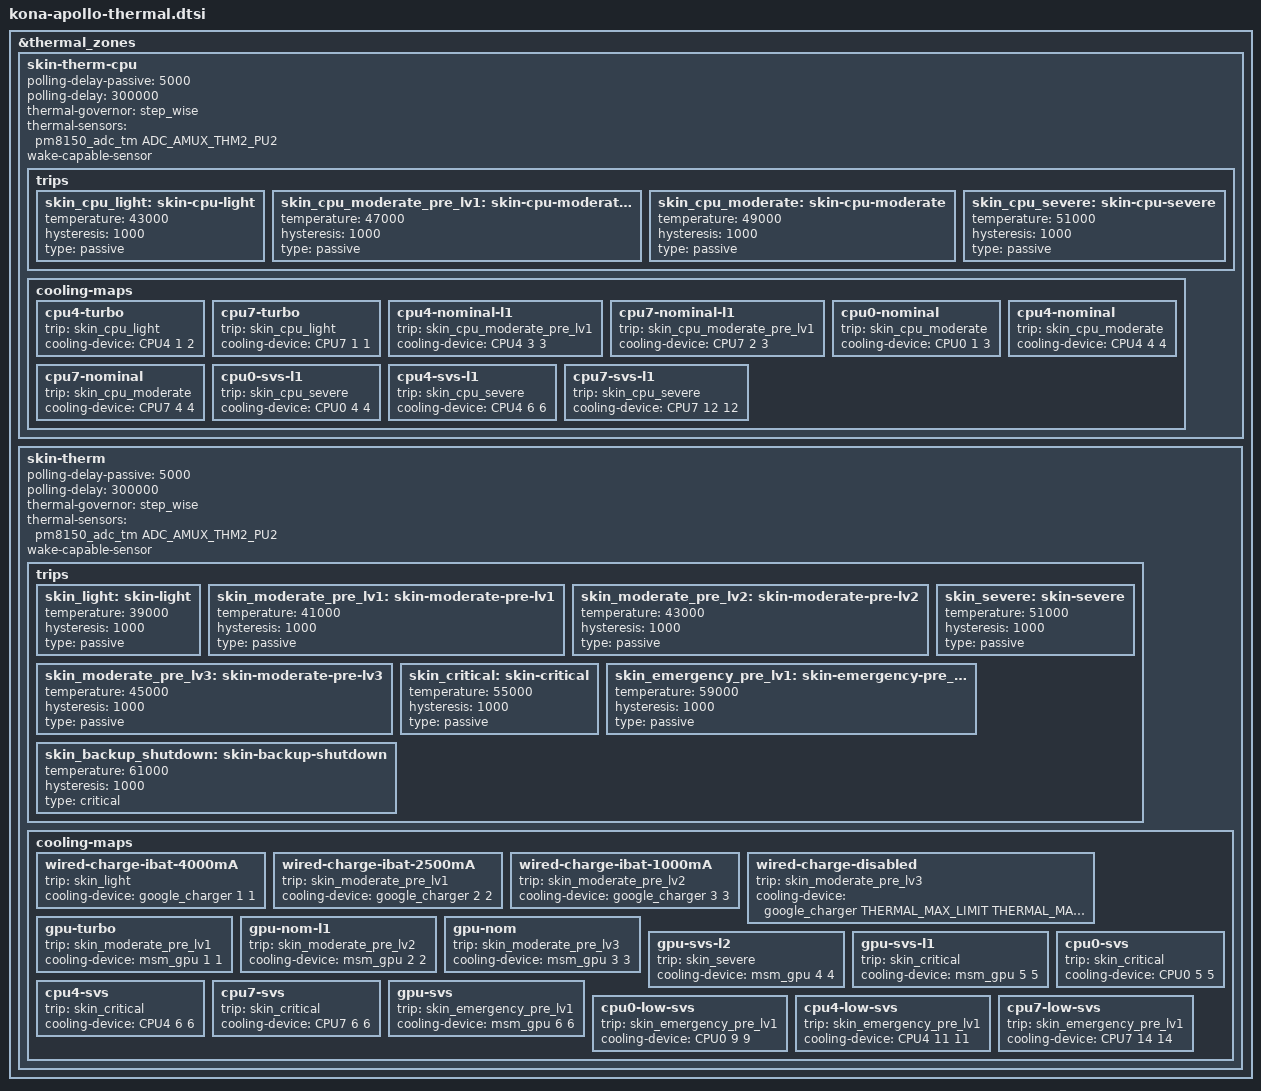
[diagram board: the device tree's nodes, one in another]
// SPDX-License-Identifier: GPL-2.0
/* Copyright (c) 2022, The Linux Foundation. All rights reserved.
 *
 * This program is free software; you can redistribute it and/or modify
 * it under the terms of the GNU General Public License version 2 and
 * only version 2 as published by the Free Software Foundation.
 *
 * This program is distributed in the hope that it will be useful,
 * but WITHOUT ANY WARRANTY; without even the implied warranty of
 * MERCHANTABILITY or FITNESS FOR A PARTICULAR PURPOSE.  See the
 * GNU General Public License for more details.
 */

#include <dt-bindings/thermal/thermal.h>

&thermal_zones {
	skin-therm-cpu {
		polling-delay-passive = <5000>;
		polling-delay = <300000>;
		thermal-governor = "step_wise";
		thermal-sensors = <&pm8150_adc_tm ADC_AMUX_THM2_PU2>;
		wake-capable-sensor;
		trips {
			skin_cpu_light: skin-cpu-light {
				temperature = <43000>;
				hysteresis = <1000>;
				type = "passive";
			};
			skin_cpu_moderate_pre_lv1: skin-cpu-moderate-pre-lv1 {
				temperature = <47000>;
				hysteresis = <1000>;
				type = "passive";
			};
			skin_cpu_moderate: skin-cpu-moderate {
				temperature = <49000>;
				hysteresis = <1000>;
				type = "passive";
			};
			skin_cpu_severe: skin-cpu-severe {
				temperature = <51000>;
				hysteresis = <1000>;
				type = "passive";
			};
		};
		cooling-maps {
			/* light throttling */
			cpu4-turbo {
				trip = <&skin_cpu_light>;
				cooling-device =
					<&CPU4 1 2>;
			};
			cpu7-turbo {
				trip = <&skin_cpu_light>;
				cooling-device =
					<&CPU7 1 1>;
			};
			/* moderate pre level 1 throttling */
			cpu4-nominal-l1 {
				trip = <&skin_cpu_moderate_pre_lv1>;
				cooling-device =
					<&CPU4 3 3>;
			};
			cpu7-nominal-l1 {
				trip = <&skin_cpu_moderate_pre_lv1>;
				cooling-device =
					<&CPU7 2 3>;
			};
			/* moderate throttling */
			cpu0-nominal {
				trip = <&skin_cpu_moderate>;
				cooling-device =
					<&CPU0 1 3>;
			};
			cpu4-nominal {
				trip = <&skin_cpu_moderate>;
				cooling-device =
					<&CPU4 4 4>;
			};
			cpu7-nominal {
				trip = <&skin_cpu_moderate>;
				cooling-device =
					<&CPU7 4 4>;
			};
			/* severe throttling */
			cpu0-svs-l1 {
				trip = <&skin_cpu_severe>;
				cooling-device =
					<&CPU0 4 4>;
			};
			cpu4-svs-l1 {
				trip = <&skin_cpu_severe>;
				cooling-device =
					<&CPU4 6 6>;
			};
			cpu7-svs-l1 {
				trip = <&skin_cpu_severe>;
				cooling-device =
					<&CPU7 12 12>;
			};
		};
	};

	skin-therm {
		polling-delay-passive = <5000>;
		polling-delay = <300000>;
		thermal-governor = "step_wise";
		thermal-sensors = <&pm8150_adc_tm ADC_AMUX_THM2_PU2>;
		wake-capable-sensor;
		trips {
			skin_light: skin-light {
				temperature = <39000>;
				hysteresis = <1000>;
				type = "passive";
			};
			skin_moderate_pre_lv1: skin-moderate-pre-lv1 {
				temperature = <41000>;
				hysteresis = <1000>;
				type = "passive";
			};
			skin_moderate_pre_lv2: skin-moderate-pre-lv2 {
				temperature = <43000>;
				hysteresis = <1000>;
				type = "passive";
			};
			skin_moderate_pre_lv3: skin-moderate-pre-lv3 {
				temperature = <45000>;
				hysteresis = <1000>;
				type = "passive";
			};
			skin_severe: skin-severe {
				temperature = <51000>;
				hysteresis = <1000>;
				type = "passive";
			};
			skin_critical: skin-critical {
				temperature = <55000>;
				hysteresis = <1000>;
				type = "passive";
			};
			skin_emergency_pre_lv1: skin-emergency-pre_lv1 {
				temperature = <59000>;
				hysteresis = <1000>;
				type = "passive";
			};
			skin_backup_shutdown: skin-backup-shutdown {
				temperature = <61000>;
				hysteresis = <1000>;
				type = "critical";
			};
		};
		cooling-maps {
			/* light throttling */
			wired-charge-ibat-4000mA {
				trip = <&skin_light>;
				cooling-device =
					<&google_charger 1 1>;
			};
			/* moderate pre level 1 throttling */
			wired-charge-ibat-2500mA {
				trip = <&skin_moderate_pre_lv1>;
				cooling-device =
					<&google_charger 2 2>;
			};
			/* moderate pre level 2 throttling */
			wired-charge-ibat-1000mA {
				trip = <&skin_moderate_pre_lv2>;
				cooling-device =
					<&google_charger 3 3>;
			};
			/* severe throttling */
			wired-charge-disabled {
				trip = <&skin_moderate_pre_lv3>;
				cooling-device = <&google_charger
					THERMAL_MAX_LIMIT THERMAL_MAX_LIMIT>;
			};
			/* moderate pre level 1 throttling */
			gpu-turbo {
				trip = <&skin_moderate_pre_lv1>;
				cooling-device =
					<&msm_gpu 1 1>;
			};
			/* moderate pre level 2 throttling */
			gpu-nom-l1 {
				trip = <&skin_moderate_pre_lv2>;
				cooling-device =
					<&msm_gpu 2 2>;
			};
			/* moderate pre level 3 throttling */
			gpu-nom {
				trip = <&skin_moderate_pre_lv3>;
				cooling-device =
					<&msm_gpu 3 3>;
			};
			/* severe throttling */
			gpu-svs-l2 {
				trip = <&skin_severe>;
				cooling-device =
					<&msm_gpu 4 4>;
			};
			/* critical throttling */
			gpu-svs-l1 {
				trip = <&skin_critical>;
				cooling-device =
					<&msm_gpu 5 5>;
			};
			cpu0-svs {
				trip = <&skin_critical>;
				cooling-device =
					<&CPU0 5 5>;
			};
			cpu4-svs {
				trip = <&skin_critical>;
				cooling-device =
					<&CPU4 6 6>;
			};
			cpu7-svs {
				trip = <&skin_critical>;
				cooling-device =
					<&CPU7 6 6>;
			};
			/* emergency pre level 1 throttling */
			gpu-svs {
				trip = <&skin_emergency_pre_lv1>;
				cooling-device =
					<&msm_gpu 6 6>;
			};
			cpu0-low-svs {
				trip = <&skin_emergency_pre_lv1>;
				cooling-device =
					<&CPU0 9 9>;
			};
			cpu4-low-svs {
				trip = <&skin_emergency_pre_lv1>;
				cooling-device =
					<&CPU4 11 11>;
			};
			cpu7-low-svs {
				trip = <&skin_emergency_pre_lv1>;
				cooling-device =
					<&CPU7 14 14>;
			};
		};
	};
};
